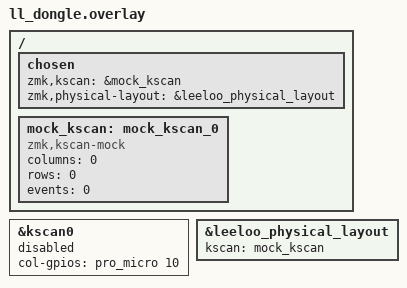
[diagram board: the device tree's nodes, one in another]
#include "ll_peripheral.dtsi"
#include "leeloo_physical_layout.dtsi"

/ {
    chosen {
        zmk,kscan = &mock_kscan;
        zmk,physical-layout = &leeloo_physical_layout;
    };

    mock_kscan: mock_kscan_0 {
        compatible = "zmk,kscan-mock";
        columns = <0>;
        rows = <0>;
        events = <0>;
    };
};

&kscan0 {
    status = "disabled";
    col-gpios = <&pro_micro 10 GPIO_ACTIVE_HIGH>;
};

&leeloo_physical_layout {
    kscan = <&mock_kscan>;
};

